# MSP430FR5962 register map
File version: 2.1
CPU: MSP430FR5962 r2p1, little endian, MPU, no FPU, 3 interrupt priority bits
Registers are 16-bit, read-write, reset 0x0 unless marked. A register's access mark holds for its fields unless they carry their own. Offsets are from the block's base; [hi:lo] are bit positions; {n}, {i} and the like mark numbered series.

## PC
Base 0x00000200
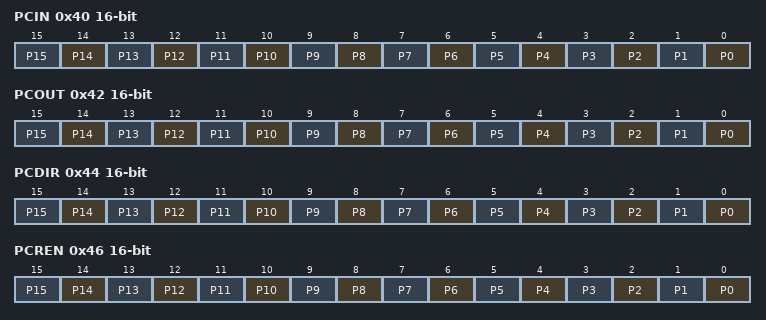
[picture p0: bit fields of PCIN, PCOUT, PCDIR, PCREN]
0x40 PCIN — Port C Input
  [n] P{n} (n=0..15)
0x42 PCOUT — Port C Output
  [n] P{n} (n=0..15)
0x44 PCDIR — Port C Direction
  [n] P{n} (n=0..15)
0x46 PCREN — Port C Resistor Enable
  [n] P{n} (n=0..15)
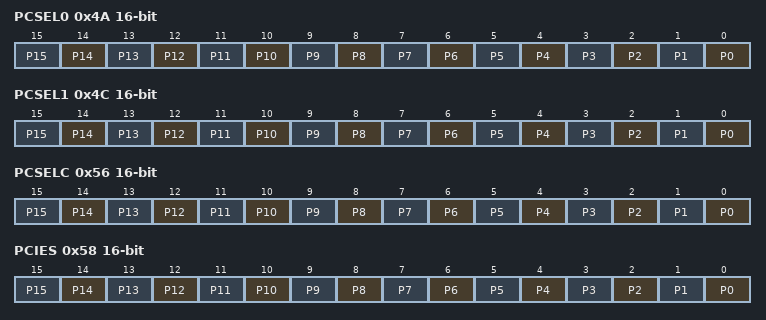
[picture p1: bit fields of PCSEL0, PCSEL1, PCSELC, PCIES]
0x4A PCSEL0 — Port C Select 0
  [n] P{n} (n=0..15)
0x4C PCSEL1 — Port C Select 1
  [n] P{n} (n=0..15)
0x56 PCSELC — Port C Complement Select
  [n] P{n} (n=0..15)
0x58 PCIES — Port C Interrupt Edge Select
  [n] P{n} (n=0..15)
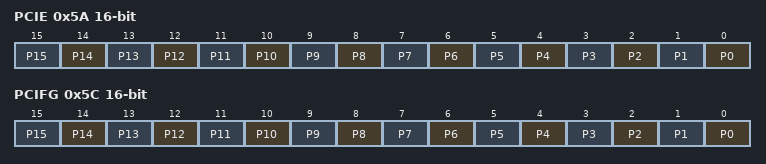
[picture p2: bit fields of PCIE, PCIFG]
0x5A PCIE — Port C Interrupt Enable
  [n] P{n} (n=0..15)
0x5C PCIFG — Port C Interrupt Flag
  [n] P{n} (n=0..15)

## P5
Base 0x00000200
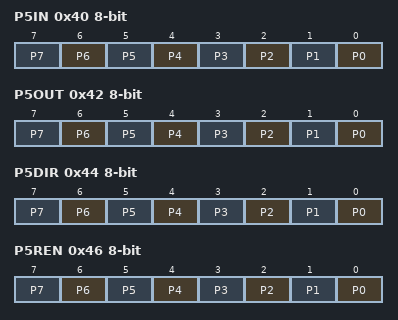
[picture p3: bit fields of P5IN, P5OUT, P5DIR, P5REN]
0x40 P5IN 8-bit — Port 5 Input
  [n] P{n} (n=0..7)
0x42 P5OUT 8-bit — Port 5 Output
  [n] P{n} (n=0..7)
0x44 P5DIR 8-bit — Port 5 Direction
  [n] P{n} (n=0..7)
0x46 P5REN 8-bit — Port 5 Resistor Enable
  [n] P{n} (n=0..7)
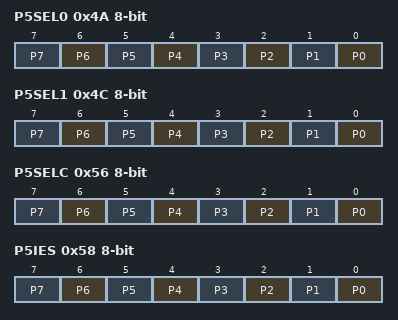
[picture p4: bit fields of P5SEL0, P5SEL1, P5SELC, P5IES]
0x4A P5SEL0 8-bit — Port 5 Select 0
  [n] P{n} (n=0..7)
0x4C P5SEL1 8-bit — Port 5 Select 1
  [n] P{n} (n=0..7)
0x4E P5IV — Port 5 Interrupt Vector Register
  [4:0] P5IV — [4:0] Port 5 interrupt vector value
    0=NONE (No interrupt pending); 2=P5IFG0 (Interrupt Source: Port 5.0 interrupt; Interrupt Flag: P5IFG0; Interrupt Priority: Highest); 4=P5IFG1 (Interrupt Source: Port 5.1 interrupt; Interrupt Flag: P5IFG1); 6=P5IFG2 (Interrupt Source: Port 5.2 interrupt; Interrupt Flag: P5IFG2); 8=P5IFG3 (Interrupt Source: Port 5.3 interrupt; Interrupt Flag: P5IFG3); 10=P5IFG4 (Interrupt Source: Port 5.4 interrupt; Interrupt Flag: P5IFG4); 12=P5IFG5 (Interrupt Source: Port 5.5 interrupt; Interrupt Flag: P5IFG5); 14=P5IFG6 (Interrupt Source: Port 5.6 interrupt; Interrupt Flag: P5IFG6); 16=P5IFG7 (Interrupt Source: Port 5.7 interrupt; Interrupt Flag: P5IFG7; Interrupt Priority: Lowest)
0x56 P5SELC 8-bit — Port 5 Complement Select
  [n] P{n} (n=0..7)
0x58 P5IES 8-bit — Port 5 Interrupt Edge Select
  [n] P{n} (n=0..7)
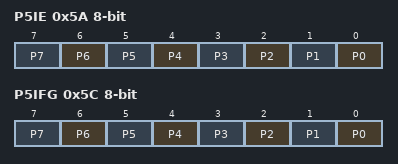
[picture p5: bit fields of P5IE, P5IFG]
0x5A P5IE 8-bit — Port 5 Interrupt Enable
  [n] P{n} (n=0..7)
0x5C P5IFG 8-bit — Port 5 Interrupt Flag
  [n] P{n} (n=0..7)

## P6
Base 0x00000200
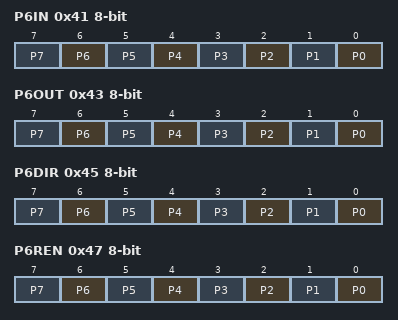
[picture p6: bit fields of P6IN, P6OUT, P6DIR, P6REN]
0x41 P6IN 8-bit — Port 6 Input
  [n] P{n} (n=0..7)
0x43 P6OUT 8-bit — Port 6 Output
  [n] P{n} (n=0..7)
0x45 P6DIR 8-bit — Port 6 Direction
  [n] P{n} (n=0..7)
0x47 P6REN 8-bit — Port 6 Resistor Enable
  [n] P{n} (n=0..7)
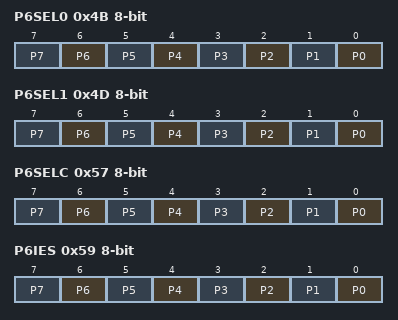
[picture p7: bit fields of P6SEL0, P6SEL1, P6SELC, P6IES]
0x4B P6SEL0 8-bit — Port 6 Select 0
  [n] P{n} (n=0..7)
0x4D P6SEL1 8-bit — Port 6 Select 1
  [n] P{n} (n=0..7)
0x57 P6SELC 8-bit — Port 6 Complement Select
  [n] P{n} (n=0..7)
0x59 P6IES 8-bit — Port 6 Interrupt Edge Select
  [n] P{n} (n=0..7)
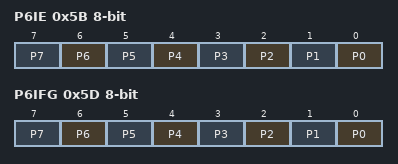
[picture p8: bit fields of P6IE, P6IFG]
0x5B P6IE 8-bit — Port 6 Interrupt Enable
  [n] P{n} (n=0..7)
0x5D P6IFG 8-bit — Port 6 Interrupt Flag
  [n] P{n} (n=0..7)
0x5E P6IV — Port 6 Interrupt Vector Register
  [4:0] P6IV — [4:0] Port 6 interrupt vector value
    0=NONE (No interrupt pending); 2=P6IFG0 (Interrupt Source: Port 6.0 interrupt; Interrupt Flag: P6IFG0; Interrupt Priority: Highest); 4=P6IFG1 (Interrupt Source: Port 6.1 interrupt; Interrupt Flag: P6IFG1); 6=P6IFG2 (Interrupt Source: Port 6.2 interrupt; Interrupt Flag: P6IFG2); 8=P6IFG3 (Interrupt Source: Port 6.3 interrupt; Interrupt Flag: P6IFG3); 10=P6IFG4 (Interrupt Source: Port 6.4 interrupt; Interrupt Flag: P6IFG4); 12=P6IFG5 (Interrupt Source: Port 6.5 interrupt; Interrupt Flag: P6IFG5); 14=P6IFG6 (Interrupt Source: Port 6.6 interrupt; Interrupt Flag: P6IFG6); 16=P6IFG7 (Interrupt Source: Port 6.7 interrupt; Interrupt Flag: P6IFG7; Interrupt Priority: Lowest)

## PD
Base 0x00000200
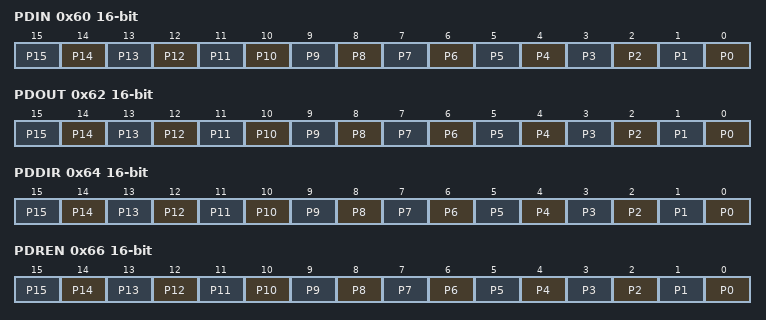
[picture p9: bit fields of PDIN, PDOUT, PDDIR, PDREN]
0x60 PDIN — Port D Input
  [n] P{n} (n=0..15)
0x62 PDOUT — Port D Output
  [n] P{n} (n=0..15)
0x64 PDDIR — Port D Direction
  [n] P{n} (n=0..15)
0x66 PDREN — Port D Resistor Enable
  [n] P{n} (n=0..15)
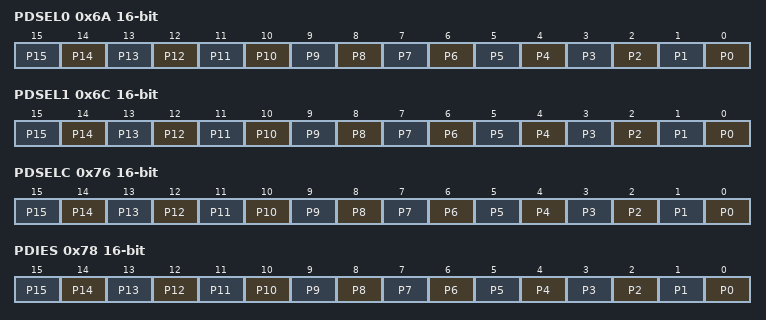
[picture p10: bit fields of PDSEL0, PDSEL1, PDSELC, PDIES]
0x6A PDSEL0 — Port D Select 0
  [n] P{n} (n=0..15)
0x6C PDSEL1 — Port D Select 1
  [n] P{n} (n=0..15)
0x76 PDSELC — Port D Complement Select
  [n] P{n} (n=0..15)
0x78 PDIES — Port D Interrupt Edge Select
  [n] P{n} (n=0..15)
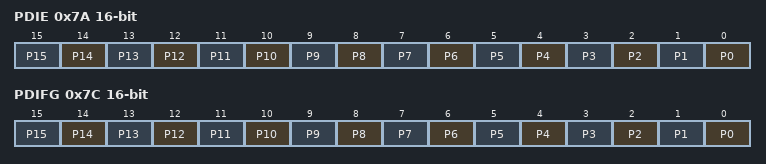
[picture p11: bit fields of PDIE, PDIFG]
0x7A PDIE — Port D Interrupt Enable
  [n] P{n} (n=0..15)
0x7C PDIFG — Port D Interrupt Flag
  [n] P{n} (n=0..15)
